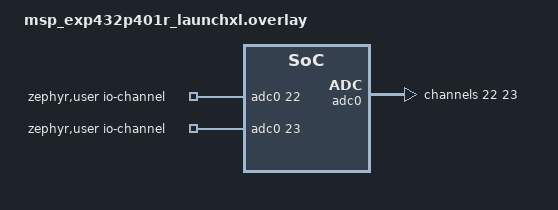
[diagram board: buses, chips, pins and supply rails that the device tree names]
/*
 * Copyright (c) 2026 Gail Rojas <gailroco@gmail.com>
 *
 * SPDX-License-Identifier: Apache-2.0
 */

#include <dt-bindings/adc/adc.h>

/ {
	zephyr,user {
		io-channels = <&adc0 22>, <&adc0 23>;
	};
};

&adc0 {
	status = "okay";
	#address-cells = <1>;
	#size-cells = <0>;

	channel@16 {
		reg = <22>;
		zephyr,gain = "ADC_GAIN_1";
		zephyr,reference = "ADC_REF_INTERNAL";
		zephyr,acquisition-time = <ADC_ACQ_TIME_DEFAULT>;
		zephyr,resolution = <14>;
	};

	channel@17 {
		reg = <23>;
		zephyr,gain = "ADC_GAIN_1";
		zephyr,reference = "ADC_REF_VDD_1";
		zephyr,acquisition-time = <ADC_ACQ_TIME_DEFAULT>;
		zephyr,resolution = <14>;
	};
};
